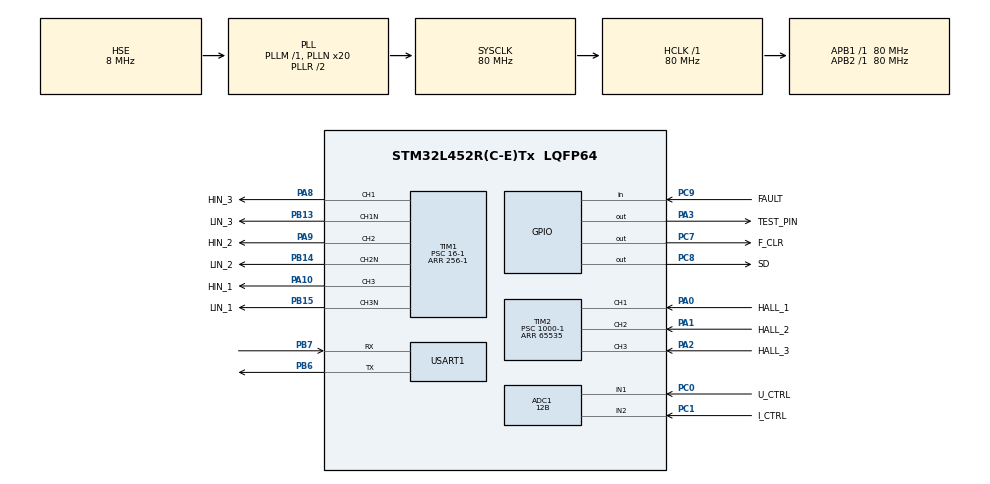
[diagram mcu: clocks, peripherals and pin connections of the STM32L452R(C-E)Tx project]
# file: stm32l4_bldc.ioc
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ADC1.Channel-0\#ChannelRegularConversion=ADC_CHANNEL_1
ADC1.Channel-1\#ChannelRegularConversion=ADC_CHANNEL_2
ADC1.Channel-2\#ChannelRegularConversion=ADC_CHANNEL_VREFINT
ADC1.ClockPrescaler=ADC_CLOCK_ASYNC_DIV128
ADC1.ContinuousConvMode=ENABLE
ADC1.DMAContinuousRequests=ENABLE
ADC1.DataAlign=ADC_DATAALIGN_RIGHT
ADC1.DiscontinuousConvMode=DISABLE
ADC1.EOCSelection=ADC_EOC_SINGLE_CONV
ADC1.EnableAnalogWatchDog1=false
ADC1.EnableAnalogWatchDog2=false
ADC1.EnableAnalogWatchDog3=false
ADC1.EnableInjectedConversion=DISABLE
ADC1.EnableRegularConversion=ENABLE
ADC1.ExternalTrigConv=ADC_SOFTWARE_START
ADC1.ExternalTrigConvEdge=ADC_EXTERNALTRIGCONVEDGE_NONE
ADC1.LowPowerAutoWait=DISABLE
ADC1.NbrOfConversion=3
ADC1.NbrOfConversionFlag=1
ADC1.OffsetNumber-0\#ChannelRegularConversion=ADC_OFFSET_NONE
ADC1.OffsetNumber-1\#ChannelRegularConversion=ADC_OFFSET_NONE
ADC1.OffsetNumber-2\#ChannelRegularConversion=ADC_OFFSET_NONE
ADC1.Overrun=ADC_OVR_DATA_PRESERVED
ADC1.OversamplingMode=DISABLE
ADC1.Rank-0\#ChannelRegularConversion=1
ADC1.Rank-1\#ChannelRegularConversion=2
ADC1.Rank-2\#ChannelRegularConversion=3
ADC1.Resolution=ADC_RESOLUTION_12B
ADC1.SamplingTime-0\#ChannelRegularConversion=ADC_SAMPLETIME_640CYCLES_5
ADC1.SamplingTime-1\#ChannelRegularConversion=ADC_SAMPLETIME_640CYCLES_5
ADC1.SamplingTime-2\#ChannelRegularConversion=ADC_SAMPLETIME_640CYCLES_5
ADC1.ScanConvMode=ADC_SCAN_ENABLE
ADC1.master=1
Dma.ADC1.0.Direction=DMA_PERIPH_TO_MEMORY
Dma.ADC1.0.Instance=DMA1_Channel1
Dma.ADC1.0.MemDataAlignment=DMA_MDATAALIGN_HALFWORD
Dma.ADC1.0.MemInc=DMA_MINC_ENABLE
Dma.ADC1.0.Mode=DMA_CIRCULAR
Dma.ADC1.0.PeriphDataAlignment=DMA_PDATAALIGN_HALFWORD
Dma.ADC1.0.PeriphInc=DMA_PINC_DISABLE
Dma.ADC1.0.Priority=DMA_PRIORITY_LOW
Dma.Request0=ADC1
FREERTOS.Tasks01=defaultTask,0,128,StartDefaultTask,Default,NULL,Dynamic,NULL,NULL;MC_Task,1,256,Start_MC_Task,Default,NULL,Dynamic,NULL,NULL
FREERTOS.configTOTAL_HEAP_SIZE=4096
Mcu.Family=STM32L4
Mcu.Name=STM32L452R(C-E)Tx
Mcu.Package=LQFP64
NVIC.DMA1_Channel1_IRQn=true\:5\:0\:false\:false\:true\:true\:false
NVIC.PriorityGroup=NVIC_PRIORITYGROUP_4
NVIC.TIM1_TRG_COM_IRQn=true\:5\:0\:false\:false\:true\:true\:true
NVIC.TIM2_IRQn=true\:5\:0\:false\:false\:true\:true\:true
NVIC.USART1_IRQn=true\:5\:0\:false\:false\:true\:true\:true
PA0.GPIO_Label=HALL_1
PA0.GPIO_PuPd=GPIO_PULLUP
PA0.GPIO_Speed=GPIO_SPEED_FREQ_VERY_HIGH
PA0.Signal=S_TIM2_CH1
PA1.GPIO_Label=HALL_2
PA1.GPIO_PuPd=GPIO_PULLUP
PA1.GPIO_Speed=GPIO_SPEED_FREQ_VERY_HIGH
PA1.Signal=S_TIM2_CH2
PA10.GPIO_Label=HIN_1
PA10.GPIO_ModeDefaultPP=GPIO_MODE_AF_OD
PA10.GPIO_PuPd=GPIO_PULLUP
PA10.GPIO_Speed=GPIO_SPEED_FREQ_VERY_HIGH
PA10.Signal=S_TIM1_CH3
PA13\ (JTMS/SWDIO).Mode=Serial_Wire
PA13\ (JTMS/SWDIO).Signal=SYS_JTMS-SWDIO
PA14\ (JTCK/SWCLK).Mode=Serial_Wire
PA14\ (JTCK/SWCLK).Signal=SYS_JTCK-SWCLK
PA2.GPIO_Label=HALL_3
PA2.GPIO_PuPd=GPIO_PULLUP
PA2.GPIO_Speed=GPIO_SPEED_FREQ_VERY_HIGH
PA2.Signal=S_TIM2_CH3
PA3.GPIO_Label=TEST_PIN
PA3.Signal=GPIO_Output
PA8.GPIO_Label=HIN_3
PA8.GPIO_ModeDefaultPP=GPIO_MODE_AF_OD
PA8.GPIO_PuPd=GPIO_PULLUP
PA8.GPIO_Speed=GPIO_SPEED_FREQ_VERY_HIGH
PA8.Signal=S_TIM1_CH1
PA9.GPIO_Label=HIN_2
PA9.GPIO_ModeDefaultPP=GPIO_MODE_AF_OD
PA9.GPIO_PuPd=GPIO_PULLUP
PA9.GPIO_Speed=GPIO_SPEED_FREQ_VERY_HIGH
PA9.Signal=S_TIM1_CH2
PB13.GPIO_Label=LIN_3
PB13.GPIO_ModeDefaultPP=GPIO_MODE_AF_OD
PB13.GPIO_PuPd=GPIO_PULLUP
PB13.GPIO_Speed=GPIO_SPEED_FREQ_VERY_HIGH
PB13.Mode=PWM Generation1 CH1 CH1N
PB13.Signal=TIM1_CH1N
PB14.GPIO_Label=LIN_2
PB14.GPIO_ModeDefaultPP=GPIO_MODE_AF_OD
PB14.GPIO_PuPd=GPIO_PULLUP
PB14.GPIO_Speed=GPIO_SPEED_FREQ_VERY_HIGH
PB14.Mode=PWM Generation2 CH2 CH2N
PB14.Signal=TIM1_CH2N
PB15.GPIO_Label=LIN_1
PB15.GPIO_ModeDefaultPP=GPIO_MODE_AF_OD
PB15.GPIO_PuPd=GPIO_PULLUP
PB15.GPIO_Speed=GPIO_SPEED_FREQ_VERY_HIGH
PB15.Mode=PWM Generation3 CH3 CH3N
PB15.Signal=TIM1_CH3N
PB6.Mode=Asynchronous
PB6.Signal=USART1_TX
PB7.Mode=Asynchronous
PB7.Signal=USART1_RX
PC0.GPIO_Label=U_CTRL
PC0.Signal=ADCx_IN1
PC1.GPIO_Label=I_CTRL
PC1.Signal=ADCx_IN2
PC7.GPIO_Label=F_CLR
PC7.GPIO_ModeDefaultOutputPP=GPIO_MODE_OUTPUT_OD
PC7.GPIO_PuPd=GPIO_PULLUP
PC7.GPIO_Speed=GPIO_SPEED_FREQ_VERY_HIGH
PC7.PinState=GPIO_PIN_SET
PC7.Signal=GPIO_Output
PC8.GPIO_Label=SD
PC8.GPIO_ModeDefaultOutputPP=GPIO_MODE_OUTPUT_OD
PC8.GPIO_PuPd=GPIO_PULLUP
PC8.GPIO_Speed=GPIO_SPEED_FREQ_VERY_HIGH
PC8.Signal=GPIO_Output
PC9.GPIO_Label=FAULT
PC9.GPIO_PuPd=GPIO_PULLUP
PC9.Signal=GPIO_Input
PH0-OSC_IN\ (PH0).Mode=HSE-External-Oscillator
PH0-OSC_IN\ (PH0).Signal=RCC_OSC_IN
PH1-OSC_OUT\ (PH1).Mode=HSE-External-Oscillator
PH1-OSC_OUT\ (PH1).Signal=RCC_OSC_OUT
ProjectManager.HeapSize=0x2000
ProjectManager.StackSize=0x4000
ProjectManager.TargetToolchain=MDK-ARM V5
RCC.ADCFreq_Value=32000000
RCC.AHBFreq_Value=80000000
RCC.APB1Freq_Value=80000000
RCC.APB1TimFreq_Value=80000000
RCC.APB2Freq_Value=80000000
RCC.APB2TimFreq_Value=80000000
RCC.CortexFreq_Value=80000000
RCC.HCLKFreq_Value=80000000
RCC.HSE_VALUE=8000000
RCC.HSI48_VALUE=48000000
RCC.HSI_VALUE=16000000
RCC.LSE_VALUE=32768
RCC.MSI_VALUE=4000000
RCC.PLLN=20
RCC.PLLSourceVirtual=RCC_PLLSOURCE_HSE
RCC.SYSCLKFreq_VALUE=80000000
RCC.SYSCLKSource=RCC_SYSCLKSOURCE_PLLCLK
RCC.USBFreq_Value=32000000
RCC.VCOOutputFreq_Value=160000000
SH.ADCx_IN1.0=ADC1_IN1,IN1-Single-Ended
SH.ADCx_IN2.0=ADC1_IN2,IN2-Single-Ended
SH.S_TIM1_CH1.0=TIM1_CH1,PWM Generation1 CH1 CH1N
SH.S_TIM1_CH2.0=TIM1_CH2,PWM Generation2 CH2 CH2N
SH.S_TIM1_CH3.0=TIM1_CH3,PWM Generation3 CH3 CH3N
SH.S_TIM2_CH1.0=TIM2_CH1,Xored_Inputs_Hall_Sensor_Interface
SH.S_TIM2_CH2.0=TIM2_CH2,Xored_Inputs_Hall_Sensor_Interface
SH.S_TIM2_CH3.0=TIM2_CH3,Xored_Inputs_Hall_Sensor_Interface
TIM1.AutomaticOutput=TIM_AUTOMATICOUTPUT_ENABLE
TIM1.Channel-PWM\ Generation1\ CH1\ CH1N=TIM_CHANNEL_1
TIM1.Channel-PWM\ Generation2\ CH2\ CH2N=TIM_CHANNEL_2
TIM1.Channel-PWM\ Generation3\ CH3\ CH3N=TIM_CHANNEL_3
TIM1.DeadTime=7
TIM1.OffStateIDLEMode=TIM_OSSI_ENABLE
TIM1.OffStateRunMode=TIM_OSSR_ENABLE
TIM1.Period=256-1
TIM1.Prescaler=16-1
TIM1.Pulse-PWM\ Generation1\ CH1\ CH1N=10
TIM1.Pulse-PWM\ Generation2\ CH2\ CH2N=10
TIM1.Pulse-PWM\ Generation3\ CH3\ CH3N=10
TIM2.IC1Filter=0xF
TIM2.Period=65535
TIM2.Prescaler=1000-1
USART1.VirtualMode-Asynchronous=VM_ASYNC
USART1.WordLength=WORDLENGTH_8B
VP_ADC1_Vref_Input.Mode=IN-Vrefint
VP_FREERTOS_VS_ENABLE.Mode=Enabled
VP_TIM1_VS_ClockSourceINT.Mode=Internal
VP_TIM1_VS_ClockSourceITR.Mode=TriggerSource_ITR1
VP_TIM2_VS_ClockSourceINT.Mode=Internal
board=stm32l4_bldc

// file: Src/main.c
/**
  ******************************************************************************
  * File Name          : main.c
  * Description        : Main program body
  ******************************************************************************
  * This notice applies to any and all portions of this file
  * that are not between comment pairs USER CODE BEGIN and
  * USER CODE END. Other portions of this file, whether
  * inserted by the user or by software development tools
  * are owned by their respective copyright owners.
  *
  * Copyright (c) 2018 STMicroelectronics International N.V.
  * All rights reserved.
  *
  * Redistribution and use in source and binary forms, with or without
  * modification, are permitted, provided that the following conditions are met:
  *
  * 1. Redistribution of source code must retain the above copyright notice,
  *    this list of conditions and the following disclaimer.
  * 2. Redistributions in binary form must reproduce the above copyright notice,
  *    this list of conditions and the following disclaimer in the documentation
  *    and/or other materials provided with the distribution.
  * 3. Neither the name of STMicroelectronics nor the names of other
  *    contributors to this software may be used to endorse or promote products
  *    derived from this software without specific written permission.
  * 4. This software, including modifications and/or derivative works of this
  *    software, must execute solely and exclusively on microcontroller or
  *    microprocessor devices manufactured by or for STMicroelectronics.
  * 5. Redistribution and use of this software other than as permitted under
  *    this license is void and will automatically terminate your rights under
  *    this license.
  *
  * THIS SOFTWARE IS PROVIDED BY STMICROELECTRONICS AND CONTRIBUTORS "AS IS"
  * AND ANY EXPRESS, IMPLIED OR STATUTORY WARRANTIES, INCLUDING, BUT NOT
  * LIMITED TO, THE IMPLIED WARRANTIES OF MERCHANTABILITY, FITNESS FOR A
  * PARTICULAR PURPOSE AND NON-INFRINGEMENT OF THIRD PARTY INTELLECTUAL PROPERTY
  * RIGHTS ARE DISCLAIMED TO THE FULLEST EXTENT PERMITTED BY LAW. IN NO EVENT
  * SHALL STMICROELECTRONICS OR CONTRIBUTORS BE LIABLE FOR ANY DIRECT, INDIRECT,
  * INCIDENTAL, SPECIAL, EXEMPLARY, OR CONSEQUENTIAL DAMAGES (INCLUDING, BUT NOT
  * LIMITED TO, PROCUREMENT OF SUBSTITUTE GOODS OR SERVICES; LOSS OF USE, DATA,
  * OR PROFITS; OR BUSINESS INTERRUPTION) HOWEVER CAUSED AND ON ANY THEORY OF
  * LIABILITY, WHETHER IN CONTRACT, STRICT LIABILITY, OR TORT (INCLUDING
  * NEGLIGENCE OR OTHERWISE) ARISING IN ANY WAY OUT OF THE USE OF THIS SOFTWARE,
  * EVEN IF ADVISED OF THE POSSIBILITY OF SUCH DAMAGE.
  *
  ******************************************************************************
  */

#include "main.h"
#include "stm32l4xx_hal.h"
#include "cmsis_os.h"
#include "adc.h"
#include "dma.h"
#include "tim.h"
#include "usart.h"
#include "gpio.h"

/* USER CODE BEGIN Includes */
#include "cmd_iface.h"
/* USER CODE END Includes */

/* USER CODE BEGIN PV */
/* Private variables ---------------------------------------------------------*/

/* USER CODE END PV */

void SystemClock_Config(void);
void MX_FREERTOS_Init(void);

/* USER CODE BEGIN PFP */
/* Private function prototypes -----------------------------------------------*/

/* USER CODE END PFP */

int main(void)
{

  /* MCU Configuration----------------------------------------------------------*/

  /* Reset of all peripherals, Initializes the Flash interface and the Systick. */
  HAL_Init();

  /* Configure the system clock */
  SystemClock_Config();

  /* Initialize all configured peripherals */
  MX_GPIO_Init();
  MX_DMA_Init();
  MX_TIM1_Init();
  MX_TIM2_Init();
  MX_ADC1_Init();
  MX_USART1_UART_Init();

  /* USER CODE BEGIN 2 */
	Cmd_Iface_Init();
  /* USER CODE END 2 */

  /* Call init function for freertos objects (in freertos.c) */
  MX_FREERTOS_Init();

  /* Start scheduler */
  osKernelStart();

  /* We should never get here as control is now taken by the scheduler */

  /* Infinite loop */
  while (1)
  {

  }

}

/** System Clock Configuration
*/
void SystemClock_Config(void)
{

  RCC_OscInitTypeDef RCC_OscInitStruct;
  RCC_ClkInitTypeDef RCC_ClkInitStruct;
  RCC_PeriphCLKInitTypeDef PeriphClkInit;

    /**Initializes the CPU, AHB and APB busses clocks
    */
  RCC_OscInitStruct.OscillatorType = RCC_OSCILLATORTYPE_HSE;
  RCC_OscInitStruct.HSEState = RCC_HSE_ON;
  RCC_OscInitStruct.PLL.PLLState = RCC_PLL_ON;
  RCC_OscInitStruct.PLL.PLLSource = RCC_PLLSOURCE_HSE;
  RCC_OscInitStruct.PLL.PLLM = 1;
  RCC_OscInitStruct.PLL.PLLN = 20;
  RCC_OscInitStruct.PLL.PLLP = RCC_PLLP_DIV7;
  RCC_OscInitStruct.PLL.PLLQ = RCC_PLLQ_DIV2;
  RCC_OscInitStruct.PLL.PLLR = RCC_PLLR_DIV2;
  if (HAL_RCC_OscConfig(&RCC_OscInitStruct) != HAL_OK)
  {
    _Error_Handler(__FILE__, __LINE__);
  }

    /**Initializes the CPU, AHB and APB busses clocks
    */
  RCC_ClkInitStruct.ClockType = RCC_CLOCKTYPE_HCLK|RCC_CLOCKTYPE_SYSCLK
                              |RCC_CLOCKTYPE_PCLK1|RCC_CLOCKTYPE_PCLK2;
  RCC_ClkInitStruct.SYSCLKSource = RCC_SYSCLKSOURCE_PLLCLK;
  RCC_ClkInitStruct.AHBCLKDivider = RCC_SYSCLK_DIV1;
  RCC_ClkInitStruct.APB1CLKDivider = RCC_HCLK_DIV1;
  RCC_ClkInitStruct.APB2CLKDivider = RCC_HCLK_DIV1;

  if (HAL_RCC_ClockConfig(&RCC_ClkInitStruct, FLASH_LATENCY_4) != HAL_OK)
  {
    _Error_Handler(__FILE__, __LINE__);
  }

  PeriphClkInit.PeriphClockSelection = RCC_PERIPHCLK_USART1|RCC_PERIPHCLK_ADC;
  PeriphClkInit.Usart1ClockSelection = RCC_USART1CLKSOURCE_PCLK2;
  PeriphClkInit.AdcClockSelection = RCC_ADCCLKSOURCE_PLLSAI1;
  PeriphClkInit.PLLSAI1.PLLSAI1Source = RCC_PLLSOURCE_HSE;
  PeriphClkInit.PLLSAI1.PLLSAI1M = 1;
  PeriphClkInit.PLLSAI1.PLLSAI1N = 8;
  PeriphClkInit.PLLSAI1.PLLSAI1P = RCC_PLLP_DIV7;
  PeriphClkInit.PLLSAI1.PLLSAI1Q = RCC_PLLQ_DIV2;
  PeriphClkInit.PLLSAI1.PLLSAI1R = RCC_PLLR_DIV2;
  PeriphClkInit.PLLSAI1.PLLSAI1ClockOut = RCC_PLLSAI1_ADC1CLK;
  if (HAL_RCCEx_PeriphCLKConfig(&PeriphClkInit) != HAL_OK)
  {
    _Error_Handler(__FILE__, __LINE__);
  }

    /**Configure the main internal regulator output voltage
    */
  if (HAL_PWREx_ControlVoltageScaling(PWR_REGULATOR_VOLTAGE_SCALE1) != HAL_OK)
  {
    _Error_Handler(__FILE__, __LINE__);
  }

    /**Configure the Systick interrupt time
    */
  HAL_SYSTICK_Config(HAL_RCC_GetHCLKFreq()/1000);

    /**Configure the Systick
    */
  HAL_SYSTICK_CLKSourceConfig(SYSTICK_CLKSOURCE_HCLK);

  /* SysTick_IRQn interrupt configuration */
  HAL_NVIC_SetPriority(SysTick_IRQn, 15, 0);
}

void _Error_Handler(char * file, int line)
{
  while(1)
  {
  }
}

/************************ (C) COPYRIGHT STMicroelectronics *****END OF FILE****/

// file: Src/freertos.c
/**
  ******************************************************************************
  * File Name          : freertos.c
  * Description        : Code for freertos applications
  ******************************************************************************
  * This notice applies to any and all portions of this file
  * that are not between comment pairs USER CODE BEGIN and
  * USER CODE END. Other portions of this file, whether
  * inserted by the user or by software development tools
  * are owned by their respective copyright owners.
  *
  * Copyright (c) 2018 STMicroelectronics International N.V.
  * All rights reserved.
  *
  * Redistribution and use in source and binary forms, with or without
  * modification, are permitted, provided that the following conditions are met:
  *
  * 1. Redistribution of source code must retain the above copyright notice,
  *    this list of conditions and the following disclaimer.
  * 2. Redistributions in binary form must reproduce the above copyright notice,
  *    this list of conditions and the following disclaimer in the documentation
  *    and/or other materials provided with the distribution.
  * 3. Neither the name of STMicroelectronics nor the names of other
  *    contributors to this software may be used to endorse or promote products
  *    derived from this software without specific written permission.
  * 4. This software, including modifications and/or derivative works of this
  *    software, must execute solely and exclusively on microcontroller or
  *    microprocessor devices manufactured by or for STMicroelectronics.
  * 5. Redistribution and use of this software other than as permitted under
  *    this license is void and will automatically terminate your rights under
  *    this license.
  *
  * THIS SOFTWARE IS PROVIDED BY STMICROELECTRONICS AND CONTRIBUTORS "AS IS"
  * AND ANY EXPRESS, IMPLIED OR STATUTORY WARRANTIES, INCLUDING, BUT NOT
  * LIMITED TO, THE IMPLIED WARRANTIES OF MERCHANTABILITY, FITNESS FOR A
  * PARTICULAR PURPOSE AND NON-INFRINGEMENT OF THIRD PARTY INTELLECTUAL PROPERTY
  * RIGHTS ARE DISCLAIMED TO THE FULLEST EXTENT PERMITTED BY LAW. IN NO EVENT
  * SHALL STMICROELECTRONICS OR CONTRIBUTORS BE LIABLE FOR ANY DIRECT, INDIRECT,
  * INCIDENTAL, SPECIAL, EXEMPLARY, OR CONSEQUENTIAL DAMAGES (INCLUDING, BUT NOT
  * LIMITED TO, PROCUREMENT OF SUBSTITUTE GOODS OR SERVICES; LOSS OF USE, DATA,
  * OR PROFITS; OR BUSINESS INTERRUPTION) HOWEVER CAUSED AND ON ANY THEORY OF
  * LIABILITY, WHETHER IN CONTRACT, STRICT LIABILITY, OR TORT (INCLUDING
  * NEGLIGENCE OR OTHERWISE) ARISING IN ANY WAY OUT OF THE USE OF THIS SOFTWARE,
  * EVEN IF ADVISED OF THE POSSIBILITY OF SUCH DAMAGE.
  *
  ******************************************************************************
  */

#include "FreeRTOS.h"
#include "task.h"
#include "cmsis_os.h"

/* USER CODE BEGIN Includes */
#include "bldc_lib.h"
#include "adc_int.h"
/* USER CODE END Includes */

osThreadId defaultTaskHandle;
osThreadId MC_TaskHandle;

/* USER CODE BEGIN Variables */
#define MC_TASK_PERIOD 10//ms
/* USER CODE END Variables */

void StartDefaultTask(void const * argument);
void Start_MC_Task(void const * argument);

void MX_FREERTOS_Init(void); /* (MISRA C 2004 rule 8.1) */

/* Hook prototypes */

/* Init FreeRTOS */

void MX_FREERTOS_Init(void) {

  /* Create the thread(s) */
  /* definition and creation of defaultTask */
  osThreadDef(defaultTask, StartDefaultTask, osPriorityNormal, 0, 128);
  defaultTaskHandle = osThreadCreate(osThread(defaultTask), NULL);

  /* definition and creation of MC_Task */
  osThreadDef(MC_Task, Start_MC_Task, osPriorityAboveNormal, 0, 256);
  MC_TaskHandle = osThreadCreate(osThread(MC_Task), NULL);

}

/* StartDefaultTask function */
void StartDefaultTask(void const * argument)
{

  /* USER CODE BEGIN StartDefaultTask */

	adcIntInit();

	osDelay(100);
//	MC_SixStep_SetSpeed(1000);//RPM
//	MC_SixStep_StartMotor();
  /* Infinite loop */
  for(;;)
  {
    osDelay(1000);
  }
  /* USER CODE END StartDefaultTask */
}

/* Start_MC_Task function */
void Start_MC_Task(void const * argument)
{
  /* USER CODE BEGIN Start_MC_Task */
	MC_SixStep_Init();
  /* Infinite loop */
  for(;;)
  {
			MC_SixStep_Handler();
			osDelay(MC_TASK_PERIOD);
  }
  /* USER CODE END Start_MC_Task */
}

/************************ (C) COPYRIGHT STMicroelectronics *****END OF FILE****/
